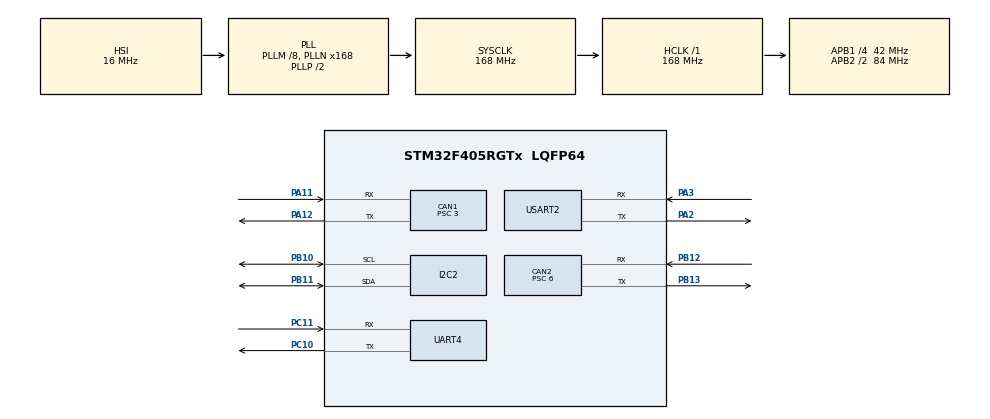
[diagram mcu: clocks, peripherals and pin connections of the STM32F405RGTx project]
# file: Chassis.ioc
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CAN1.ABOM=ENABLE
CAN1.BS1=CAN_BS1_11TQ
CAN1.BS2=CAN_BS2_2TQ
CAN1.CalculateBaudRate=1000000
CAN1.CalculateTimeBit=1000
CAN1.CalculateTimeQuantum=71.42857142857143
CAN1.NART=ENABLE
CAN1.Prescaler=3
CAN2.ABOM=ENABLE
CAN2.BS1=CAN_BS1_4TQ
CAN2.BS2=CAN_BS2_2TQ
CAN2.CalculateBaudRate=1000000
CAN2.CalculateTimeBit=1000
CAN2.CalculateTimeQuantum=142.85714285714286
CAN2.NART=ENABLE
CAN2.Prescaler=6
Dma.Request0=USART2_TX
Dma.Request1=UART4_RX
Dma.Request2=UART4_TX
Dma.UART4_RX.1.Direction=DMA_PERIPH_TO_MEMORY
Dma.UART4_RX.1.FIFOMode=DMA_FIFOMODE_DISABLE
Dma.UART4_RX.1.Instance=DMA1_Stream2
Dma.UART4_RX.1.MemDataAlignment=DMA_MDATAALIGN_BYTE
Dma.UART4_RX.1.MemInc=DMA_MINC_ENABLE
Dma.UART4_RX.1.Mode=DMA_NORMAL
Dma.UART4_RX.1.PeriphDataAlignment=DMA_PDATAALIGN_BYTE
Dma.UART4_RX.1.PeriphInc=DMA_PINC_DISABLE
Dma.UART4_RX.1.Priority=DMA_PRIORITY_HIGH
Dma.UART4_TX.2.Direction=DMA_MEMORY_TO_PERIPH
Dma.UART4_TX.2.FIFOMode=DMA_FIFOMODE_DISABLE
Dma.UART4_TX.2.Instance=DMA1_Stream4
Dma.UART4_TX.2.MemDataAlignment=DMA_MDATAALIGN_BYTE
Dma.UART4_TX.2.MemInc=DMA_MINC_ENABLE
Dma.UART4_TX.2.Mode=DMA_NORMAL
Dma.UART4_TX.2.PeriphDataAlignment=DMA_PDATAALIGN_BYTE
Dma.UART4_TX.2.PeriphInc=DMA_PINC_DISABLE
Dma.UART4_TX.2.Priority=DMA_PRIORITY_VERY_HIGH
Dma.USART2_TX.0.Direction=DMA_MEMORY_TO_PERIPH
Dma.USART2_TX.0.FIFOMode=DMA_FIFOMODE_DISABLE
Dma.USART2_TX.0.Instance=DMA1_Stream6
Dma.USART2_TX.0.MemDataAlignment=DMA_MDATAALIGN_BYTE
Dma.USART2_TX.0.MemInc=DMA_MINC_ENABLE
Dma.USART2_TX.0.Mode=DMA_NORMAL
Dma.USART2_TX.0.PeriphDataAlignment=DMA_PDATAALIGN_BYTE
Dma.USART2_TX.0.PeriphInc=DMA_PINC_DISABLE
Dma.USART2_TX.0.Priority=DMA_PRIORITY_VERY_HIGH
FREERTOS.INCLUDE_eTaskGetState=1
FREERTOS.INCLUDE_pcTaskGetTaskName=1
FREERTOS.INCLUDE_uxTaskGetStackHighWaterMark=1
FREERTOS.INCLUDE_vTaskCleanUpResources=1
FREERTOS.INCLUDE_vTaskDelayUntil=1
FREERTOS.INCLUDE_xEventGroupSetBitFromISR=1
FREERTOS.INCLUDE_xQueueGetMutexHolder=1
FREERTOS.INCLUDE_xSemaphoreGetMutexHolder=1
FREERTOS.INCLUDE_xTaskAbortDelay=1
FREERTOS.INCLUDE_xTaskGetCurrentTaskHandle=1
FREERTOS.INCLUDE_xTaskGetHandle=1
FREERTOS.INCLUDE_xTimerPendFunctionCall=1
FREERTOS.Tasks01=defaultTask,-2,128,StartDefaultTask,Default,NULL,Dynamic,NULL,NULL;offline_task,0,1024,Offline_task,As weak,NULL,Dynamic,NULL,NULL;gimbalTask,3,1024,GimbalTask,As weak,NULL,Dynamic,NULL,NULL;powerControlTas,3,1024,PowerControlTask,As weak,NULL,Dynamic,NULL,NULL;refereetask,3,1024,Refereetask,As weak,NULL,Dynamic,NULL,NULL;_ChassisCtrl,3,1024,ChassisControl_task,As weak,NULL,Dynamic,NULL,NULL
FREERTOS.configTOTAL_HEAP_SIZE=34000
FREERTOS.configUSE_TIMERS=1
Mcu.Family=STM32F4
Mcu.Name=STM32F405RGTx
Mcu.Package=LQFP64
NVIC.CAN1_RX0_IRQn=true\:5\:0\:true\:false\:true\:true\:true\:true\:true
NVIC.CAN1_RX1_IRQn=true\:5\:0\:true\:false\:true\:true\:true\:true\:true
NVIC.CAN1_TX_IRQn=true\:5\:0\:true\:false\:true\:true\:true\:true\:true
NVIC.CAN2_RX0_IRQn=true\:5\:0\:true\:false\:true\:true\:true\:true\:true
NVIC.CAN2_RX1_IRQn=true\:5\:0\:true\:false\:true\:true\:true\:true\:true
NVIC.CAN2_TX_IRQn=true\:5\:0\:true\:false\:true\:true\:true\:true\:true
NVIC.DMA1_Stream2_IRQn=true\:5\:0\:false\:false\:true\:true\:false\:true\:true
NVIC.DMA1_Stream4_IRQn=true\:5\:0\:false\:false\:true\:true\:false\:true\:true
NVIC.DMA1_Stream6_IRQn=true\:5\:0\:false\:false\:true\:true\:false\:true\:true
NVIC.PriorityGroup=NVIC_PRIORITYGROUP_4
NVIC.TIM6_DAC_IRQn=true\:15\:0\:false\:false\:true\:false\:false\:true\:true
NVIC.TimeBase=TIM6_DAC_IRQn
NVIC.TimeBaseIP=TIM6
NVIC.UART4_IRQn=true\:5\:0\:false\:false\:true\:true\:true\:true\:true
NVIC.USART2_IRQn=true\:5\:0\:false\:false\:true\:true\:true\:true\:true
PA11.Mode=CAN_Activate
PA11.Signal=CAN1_RX
PA12.Mode=CAN_Activate
PA12.Signal=CAN1_TX
PA13.Mode=Serial_Wire
PA13.Signal=SYS_JTMS-SWDIO
PA14.Mode=Serial_Wire
PA14.Signal=SYS_JTCK-SWCLK
PA2.Mode=Asynchronous
PA2.Signal=USART2_TX
PA3.Mode=Asynchronous
PA3.Signal=USART2_RX
PB10.GPIO_Pu=GPIO_PULLUP
PB10.Mode=I2C
PB10.Signal=I2C2_SCL
PB11.Mode=I2C
PB11.Signal=I2C2_SDA
PB12.Mode=CAN_Activate
PB12.Signal=CAN2_RX
PB13.Mode=CAN_Activate
PB13.Signal=CAN2_TX
PC10.Mode=Asynchronous
PC10.Signal=UART4_TX
PC11.Mode=Asynchronous
PC11.Signal=UART4_RX
PH0-OSC_IN.Mode=HSE-External-Oscillator
PH0-OSC_IN.Signal=RCC_OSC_IN
PH1-OSC_OUT.Mode=HSE-External-Oscillator
PH1-OSC_OUT.Signal=RCC_OSC_OUT
ProjectManager.HeapSize=0x200
ProjectManager.StackSize=0x400
ProjectManager.TargetToolchain=MDK-ARM V5.32
RCC.48MHZClocksFreq_Value=84000000
RCC.AHBFreq_Value=168000000
RCC.APB1CLKDivider=RCC_HCLK_DIV4
RCC.APB1Freq_Value=42000000
RCC.APB1TimFreq_Value=84000000
RCC.APB2CLKDivider=RCC_HCLK_DIV2
RCC.APB2Freq_Value=84000000
RCC.APB2TimFreq_Value=168000000
RCC.CortexFreq_Value=168000000
RCC.HCLKFreq_Value=168000000
RCC.HSE_VALUE=25000000
RCC.HSI_VALUE=16000000
RCC.LSE_VALUE=32768
RCC.PLLM=8
RCC.PLLN=168
RCC.SYSCLKFreq_VALUE=168000000
RCC.SYSCLKSource=RCC_SYSCLKSOURCE_PLLCLK
RCC.VCOOutputFreq_Value=336000000
STMicroelectronics.X-CUBE-ALGOBUILD.1.4.0.LibraryCcDSPOoLibraryJjDSPOoLibrary=true
UART4.VirtualMode=Asynchronous
USART2.VirtualMode=VM_ASYNC
VP_CRC_VS_CRC.Mode=CRC_Activate
VP_FREERTOS_VS_CMSIS_V1.Mode=CMSIS_V1
VP_STMicroelectronics.X-CUBE-ALGOBUILD_VS_DSPOoLibraryJjLibrary_1.4.0_1.4.0.Mode=DSPOoLibraryJjLibrary
VP_SYS_VS_tim6.Mode=TIM6
board=custom

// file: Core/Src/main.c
/* USER CODE BEGIN Header */
/**
  ******************************************************************************
  * @file           : main.c
  * @brief          : Main program body
  ******************************************************************************
  * @attention
  *
  * Copyright (c) 2025 STMicroelectronics.
  * All rights reserved.
  *
  * This software is licensed under terms that can be found in the LICENSE file
  * in the root directory of this software component.
  * If no LICENSE file comes with this software, it is provided AS-IS.
  *
  ******************************************************************************
  */
/* USER CODE END Header */
#include "main.h"
#include "cmsis_os.h"
#include "can.h"
#include "crc.h"
#include "dma.h"
#include "i2c.h"
#include "usart.h"
#include "gpio.h"

/* USER CODE BEGIN Includes */
#include "robot_config.h"
#include "ChassisController.h"
#include "bsp_can.h"
#include "debug.h"
#include "remote_control.h"
/* USER CODE END Includes */

void SystemClock_Config(void);
void MX_FREERTOS_Init(void);

int main(void)
{

  /* MCU Configuration--------------------------------------------------------*/

  /* Reset of all peripherals, Initializes the Flash interface and the Systick. */
  HAL_Init();

  /* Configure the system clock */
  SystemClock_Config();

  /* Initialize all configured peripherals */
  MX_GPIO_Init();
  MX_DMA_Init();
  MX_CAN1_Init();
  MX_CAN2_Init();
  MX_USART2_UART_Init();
  MX_I2C2_Init();
  MX_UART4_Init();
  MX_CRC_Init();
  /* USER CODE BEGIN 2 */

	can_filter_init();
	DWT_Init(168);

	initRemoteControl(DJI_REMOTE_CONTROL);
	setRobotType();

  /* USER CODE END 2 */

  /* Call init function for freertos objects (in cmsis_os2.c) */
  MX_FREERTOS_Init();

  /* Start scheduler */
  osKernelStart();

  /* We should never get here as control is now taken by the scheduler */

  /* Infinite loop */
  while (1)
  {

  }
}

void SystemClock_Config(void)
{
  RCC_OscInitTypeDef RCC_OscInitStruct = {0};
  RCC_ClkInitTypeDef RCC_ClkInitStruct = {0};

  /** Configure the main internal regulator output voltage
  */
  __HAL_RCC_PWR_CLK_ENABLE();
  __HAL_PWR_VOLTAGESCALING_CONFIG(PWR_REGULATOR_VOLTAGE_SCALE1);

  /** Initializes the RCC Oscillators according to the specified parameters
  * in the RCC_OscInitTypeDef structure.
  */
  RCC_OscInitStruct.OscillatorType = RCC_OSCILLATORTYPE_HSI;
  RCC_OscInitStruct.HSIState = RCC_HSI_ON;
  RCC_OscInitStruct.HSICalibrationValue = RCC_HSICALIBRATION_DEFAULT;
  RCC_OscInitStruct.PLL.PLLState = RCC_PLL_ON;
  RCC_OscInitStruct.PLL.PLLSource = RCC_PLLSOURCE_HSI;
  RCC_OscInitStruct.PLL.PLLM = 8;
  RCC_OscInitStruct.PLL.PLLN = 168;
  RCC_OscInitStruct.PLL.PLLP = RCC_PLLP_DIV2;
  RCC_OscInitStruct.PLL.PLLQ = 4;
  if (HAL_RCC_OscConfig(&RCC_OscInitStruct) != HAL_OK)
  {
    Error_Handler();
  }

  /** Initializes the CPU, AHB and APB buses clocks
  */
  RCC_ClkInitStruct.ClockType = RCC_CLOCKTYPE_HCLK|RCC_CLOCKTYPE_SYSCLK
                              |RCC_CLOCKTYPE_PCLK1|RCC_CLOCKTYPE_PCLK2;
  RCC_ClkInitStruct.SYSCLKSource = RCC_SYSCLKSOURCE_PLLCLK;
  RCC_ClkInitStruct.AHBCLKDivider = RCC_SYSCLK_DIV1;
  RCC_ClkInitStruct.APB1CLKDivider = RCC_HCLK_DIV4;
  RCC_ClkInitStruct.APB2CLKDivider = RCC_HCLK_DIV2;

  if (HAL_RCC_ClockConfig(&RCC_ClkInitStruct, FLASH_LATENCY_5) != HAL_OK)
  {
    Error_Handler();
  }
}

void HAL_TIM_PeriodElapsedCallback(TIM_HandleTypeDef *htim)
{
  if (htim->Instance == TIM6)
  {
    HAL_IncTick();
  }
}

void Error_Handler(void)
{
  __disable_irq();
  while (1)
  {
  }
}

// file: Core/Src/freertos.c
/* USER CODE BEGIN Header */
/**
  ******************************************************************************
  * File Name          : freertos.c
  * Description        : Code for freertos applications
  ******************************************************************************
  * @attention
  *
  * Copyright (c) 2025 STMicroelectronics.
  * All rights reserved.
  *
  * This software is licensed under terms that can be found in the LICENSE file
  * in the root directory of this software component.
  * If no LICENSE file comes with this software, it is provided AS-IS.
  *
  ******************************************************************************
  */
/* USER CODE END Header */

#include "FreeRTOS.h"
#include "task.h"
#include "main.h"
#include "cmsis_os.h"

/* USER CODE BEGIN Includes */
#include "Offline_Task.h"
#include "RefereeTask.h"
#include "PowerControlTask.h"
#include "GimbalTask.h"
#include "ChassisControlTask.h"

/* USER CODE END Includes */

osThreadId defaultTaskHandle;
osThreadId offline_taskHandle;
osThreadId gimbalTaskHandle;
osThreadId powerControlTasHandle;
osThreadId refereetaskHandle;
osThreadId _ChassisCtrlHandle;

void StartDefaultTask(void const * argument);
void Offline_task(void const * argument);
void GimbalTask(void const * argument);
void PowerControlTask(void const * argument);
void Refereetask(void const * argument);
void ChassisControl_task(void const * argument);

void MX_FREERTOS_Init(void); /* (MISRA C 2004 rule 8.1) */

/* GetIdleTaskMemory prototype (linked to static allocation support) */
void vApplicationGetIdleTaskMemory( StaticTask_t **ppxIdleTaskTCBBuffer, StackType_t **ppxIdleTaskStackBuffer, uint32_t *pulIdleTaskStackSize );

/* GetTimerTaskMemory prototype (linked to static allocation support) */
void vApplicationGetTimerTaskMemory( StaticTask_t **ppxTimerTaskTCBBuffer, StackType_t **ppxTimerTaskStackBuffer, uint32_t *pulTimerTaskStackSize );

/* USER CODE BEGIN GET_IDLE_TASK_MEMORY */
static StaticTask_t xIdleTaskTCBBuffer;
static StackType_t xIdleStack[configMINIMAL_STACK_SIZE];

void vApplicationGetIdleTaskMemory( StaticTask_t **ppxIdleTaskTCBBuffer, StackType_t **ppxIdleTaskStackBuffer, uint32_t *pulIdleTaskStackSize )
{
  *ppxIdleTaskTCBBuffer = &xIdleTaskTCBBuffer;
  *ppxIdleTaskStackBuffer = &xIdleStack[0];
  *pulIdleTaskStackSize = configMINIMAL_STACK_SIZE;
  /* place for user code */
}
/* USER CODE END GET_IDLE_TASK_MEMORY */

/* USER CODE BEGIN GET_TIMER_TASK_MEMORY */
static StaticTask_t xTimerTaskTCBBuffer;
static StackType_t xTimerStack[configTIMER_TASK_STACK_DEPTH];

void vApplicationGetTimerTaskMemory( StaticTask_t **ppxTimerTaskTCBBuffer, StackType_t **ppxTimerTaskStackBuffer, uint32_t *pulTimerTaskStackSize )
{
  *ppxTimerTaskTCBBuffer = &xTimerTaskTCBBuffer;
  *ppxTimerTaskStackBuffer = &xTimerStack[0];
  *pulTimerTaskStackSize = configTIMER_TASK_STACK_DEPTH;
  /* place for user code */
}
/* USER CODE END GET_TIMER_TASK_MEMORY */

void MX_FREERTOS_Init(void) {

  /* Create the thread(s) */
  /* definition and creation of defaultTask */
  osThreadDef(defaultTask, StartDefaultTask, osPriorityLow, 0, 128);
  defaultTaskHandle = osThreadCreate(osThread(defaultTask), NULL);

  /* definition and creation of offline_task */
  osThreadDef(offline_task, Offline_task, osPriorityNormal, 0, 1024);
  offline_taskHandle = osThreadCreate(osThread(offline_task), NULL);

  /* definition and creation of gimbalTask */
  osThreadDef(gimbalTask, GimbalTask, osPriorityRealtime, 0, 1024);
  gimbalTaskHandle = osThreadCreate(osThread(gimbalTask), NULL);

  /* definition and creation of powerControlTas */
  osThreadDef(powerControlTas, PowerControlTask, osPriorityRealtime, 0, 1024);
  powerControlTasHandle = osThreadCreate(osThread(powerControlTas), NULL);

  /* definition and creation of refereetask */
  osThreadDef(refereetask, Refereetask, osPriorityRealtime, 0, 1024);
  refereetaskHandle = osThreadCreate(osThread(refereetask), NULL);

  /* definition and creation of _ChassisCtrl */
  osThreadDef(_ChassisCtrl, ChassisControl_task, osPriorityRealtime, 0, 1024);
  _ChassisCtrlHandle = osThreadCreate(osThread(_ChassisCtrl), NULL);

}

void StartDefaultTask(void const * argument)
{
  for(;;)
  {
    osDelay(1);
  }
}

__weak void Offline_task(void const * argument)
{
  for(;;)
  {
    osDelay(1);
  }
}

__weak void GimbalTask(void const * argument)
{
  for(;;)
  {
    osDelay(1);
  }
}

__weak void PowerControlTask(void const * argument)
{
  for(;;)
  {
    osDelay(1);
  }
}

__weak void Refereetask(void const * argument)
{
  for(;;)
  {
    osDelay(1);
  }
}

__weak void ChassisControl_task(void const * argument)
{
  for(;;)
  {
    osDelay(1);
  }
}
